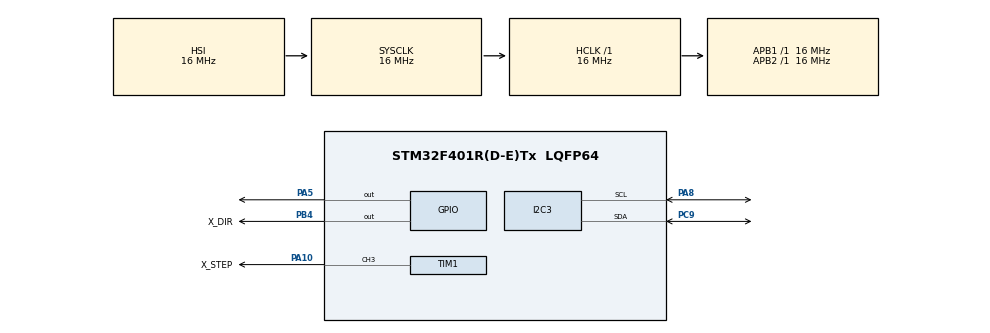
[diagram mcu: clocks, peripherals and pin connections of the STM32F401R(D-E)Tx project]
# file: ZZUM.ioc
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Mcu.Family=STM32F4
Mcu.Name=STM32F401R(D-E)Tx
Mcu.Package=LQFP64
NVIC.PriorityGroup=NVIC_PRIORITYGROUP_4
PA10.GPIO_Label=X_STEP
PA10.Signal=S_TIM1_CH3
PA5.Signal=GPIO_Output
PA8.Mode=I2C
PA8.Signal=I2C3_SCL
PB4.GPIO_Label=X_DIR
PB4.Signal=GPIO_Output
PC9.Mode=I2C
PC9.Signal=I2C3_SDA
ProjectManager.HeapSize=0x200
ProjectManager.StackSize=0x400
ProjectManager.TargetToolchain=STM32CubeIDE
RCC.AHBFreq_Value=16000000
RCC.APB1Freq_Value=16000000
RCC.APB2Freq_Value=16000000
RCC.CortexFreq_Value=16000000
RCC.HSE_VALUE=25000000
RCC.HSI_VALUE=16000000
RCC.LSE_VALUE=32768
RCC.SYSCLKFreq_VALUE=16000000
RCC.VCOOutputFreq_Value=192000000
SH.S_TIM1_CH3.0=TIM1_CH3,PWM Generation3 CH3
TIM1.Channel-PWM\ Generation3\ CH3=TIM_CHANNEL_3
board=custom

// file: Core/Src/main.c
/* USER CODE BEGIN Header */
/**
  ******************************************************************************
  * @file           : main.c
  * @brief          : Main program body
  ******************************************************************************
  * @attention
  *
  * Copyright (c) 2025 STMicroelectronics.
  * All rights reserved.
  *
  * This software is licensed under terms that can be found in the LICENSE file
  * in the root directory of this software component.
  * If no LICENSE file comes with this software, it is provided AS-IS.
  *
  ******************************************************************************
  */
/* USER CODE END Header */
#include "main.h"

I2C_HandleTypeDef hi2c3;

TIM_HandleTypeDef htim1;

void SystemClock_Config(void);
static void MX_GPIO_Init(void);
static void MX_TIM1_Init(void);
static void MX_I2C3_Init(void);

int main(void)
{

  /* MCU Configuration--------------------------------------------------------*/

  /* Reset of all peripherals, Initializes the Flash interface and the Systick. */
  HAL_Init();

  /* Configure the system clock */
  SystemClock_Config();

  /* Initialize all configured peripherals */
  MX_GPIO_Init();
  MX_TIM1_Init();
  MX_I2C3_Init();

  /* Infinite loop */
  /* USER CODE BEGIN WHILE */
  while (1)
  {
	  HAL_GPIO_TogglePin(GPIOA, GPIO_PIN_5); // LED
	  HAL_Delay(1000);                       // BLINK
    /* USER CODE END WHILE */

  }
}

void SystemClock_Config(void)
{
  RCC_OscInitTypeDef RCC_OscInitStruct = {0};
  RCC_ClkInitTypeDef RCC_ClkInitStruct = {0};

  /** Configure the main internal regulator output voltage
  */
  __HAL_RCC_PWR_CLK_ENABLE();
  __HAL_PWR_VOLTAGESCALING_CONFIG(PWR_REGULATOR_VOLTAGE_SCALE2);

  /** Initializes the RCC Oscillators according to the specified parameters
  * in the RCC_OscInitTypeDef structure.
  */
  RCC_OscInitStruct.OscillatorType = RCC_OSCILLATORTYPE_HSI;
  RCC_OscInitStruct.HSIState = RCC_HSI_ON;
  RCC_OscInitStruct.HSICalibrationValue = RCC_HSICALIBRATION_DEFAULT;
  RCC_OscInitStruct.PLL.PLLState = RCC_PLL_NONE;
  if (HAL_RCC_OscConfig(&RCC_OscInitStruct) != HAL_OK)
  {
    Error_Handler();
  }

  /** Initializes the CPU, AHB and APB buses clocks
  */
  RCC_ClkInitStruct.ClockType = RCC_CLOCKTYPE_HCLK|RCC_CLOCKTYPE_SYSCLK
                              |RCC_CLOCKTYPE_PCLK1|RCC_CLOCKTYPE_PCLK2;
  RCC_ClkInitStruct.SYSCLKSource = RCC_SYSCLKSOURCE_HSI;
  RCC_ClkInitStruct.AHBCLKDivider = RCC_SYSCLK_DIV1;
  RCC_ClkInitStruct.APB1CLKDivider = RCC_HCLK_DIV1;
  RCC_ClkInitStruct.APB2CLKDivider = RCC_HCLK_DIV1;

  if (HAL_RCC_ClockConfig(&RCC_ClkInitStruct, FLASH_LATENCY_0) != HAL_OK)
  {
    Error_Handler();
  }
}

static void MX_I2C3_Init(void)
{

  hi2c3.Instance = I2C3;
  hi2c3.Init.ClockSpeed = 100000;
  hi2c3.Init.DutyCycle = I2C_DUTYCYCLE_2;
  hi2c3.Init.OwnAddress1 = 0;
  hi2c3.Init.AddressingMode = I2C_ADDRESSINGMODE_7BIT;
  hi2c3.Init.DualAddressMode = I2C_DUALADDRESS_DISABLE;
  hi2c3.Init.OwnAddress2 = 0;
  hi2c3.Init.GeneralCallMode = I2C_GENERALCALL_DISABLE;
  hi2c3.Init.NoStretchMode = I2C_NOSTRETCH_DISABLE;
  if (HAL_I2C_Init(&hi2c3) != HAL_OK)
  {
    Error_Handler();
  }

}

static void MX_TIM1_Init(void)
{

  TIM_MasterConfigTypeDef sMasterConfig = {0};
  TIM_OC_InitTypeDef sConfigOC = {0};
  TIM_BreakDeadTimeConfigTypeDef sBreakDeadTimeConfig = {0};

  htim1.Instance = TIM1;
  htim1.Init.Prescaler = 0;
  htim1.Init.CounterMode = TIM_COUNTERMODE_UP;
  htim1.Init.Period = 65535;
  htim1.Init.ClockDivision = TIM_CLOCKDIVISION_DIV1;
  htim1.Init.RepetitionCounter = 0;
  htim1.Init.AutoReloadPreload = TIM_AUTORELOAD_PRELOAD_DISABLE;
  if (HAL_TIM_PWM_Init(&htim1) != HAL_OK)
  {
    Error_Handler();
  }
  sMasterConfig.MasterOutputTrigger = TIM_TRGO_RESET;
  sMasterConfig.MasterSlaveMode = TIM_MASTERSLAVEMODE_DISABLE;
  if (HAL_TIMEx_MasterConfigSynchronization(&htim1, &sMasterConfig) != HAL_OK)
  {
    Error_Handler();
  }
  sConfigOC.OCMode = TIM_OCMODE_PWM1;
  sConfigOC.Pulse = 0;
  sConfigOC.OCPolarity = TIM_OCPOLARITY_HIGH;
  sConfigOC.OCNPolarity = TIM_OCNPOLARITY_HIGH;
  sConfigOC.OCFastMode = TIM_OCFAST_DISABLE;
  sConfigOC.OCIdleState = TIM_OCIDLESTATE_RESET;
  sConfigOC.OCNIdleState = TIM_OCNIDLESTATE_RESET;
  if (HAL_TIM_PWM_ConfigChannel(&htim1, &sConfigOC, TIM_CHANNEL_3) != HAL_OK)
  {
    Error_Handler();
  }
  sBreakDeadTimeConfig.OffStateRunMode = TIM_OSSR_DISABLE;
  sBreakDeadTimeConfig.OffStateIDLEMode = TIM_OSSI_DISABLE;
  sBreakDeadTimeConfig.LockLevel = TIM_LOCKLEVEL_OFF;
  sBreakDeadTimeConfig.DeadTime = 0;
  sBreakDeadTimeConfig.BreakState = TIM_BREAK_DISABLE;
  sBreakDeadTimeConfig.BreakPolarity = TIM_BREAKPOLARITY_HIGH;
  sBreakDeadTimeConfig.AutomaticOutput = TIM_AUTOMATICOUTPUT_DISABLE;
  if (HAL_TIMEx_ConfigBreakDeadTime(&htim1, &sBreakDeadTimeConfig) != HAL_OK)
  {
    Error_Handler();
  }
  HAL_TIM_MspPostInit(&htim1);

}

static void MX_GPIO_Init(void)
{
  GPIO_InitTypeDef GPIO_InitStruct = {0};

  /* GPIO Ports Clock Enable */
  __HAL_RCC_GPIOA_CLK_ENABLE();
  __HAL_RCC_GPIOC_CLK_ENABLE();
  __HAL_RCC_GPIOB_CLK_ENABLE();

  /*Configure GPIO pin Output Level */
  HAL_GPIO_WritePin(GPIOA, GPIO_PIN_5, GPIO_PIN_RESET);

  /*Configure GPIO pin Output Level */
  HAL_GPIO_WritePin(X_DIR_GPIO_Port, X_DIR_Pin, GPIO_PIN_RESET);

  /*Configure GPIO pin : PA5 */
  GPIO_InitStruct.Pin = GPIO_PIN_5;
  GPIO_InitStruct.Mode = GPIO_MODE_OUTPUT_PP;
  GPIO_InitStruct.Pull = GPIO_NOPULL;
  GPIO_InitStruct.Speed = GPIO_SPEED_FREQ_LOW;
  HAL_GPIO_Init(GPIOA, &GPIO_InitStruct);

  /*Configure GPIO pin : X_DIR_Pin */
  GPIO_InitStruct.Pin = X_DIR_Pin;
  GPIO_InitStruct.Mode = GPIO_MODE_OUTPUT_PP;
  GPIO_InitStruct.Pull = GPIO_NOPULL;
  GPIO_InitStruct.Speed = GPIO_SPEED_FREQ_LOW;
  HAL_GPIO_Init(X_DIR_GPIO_Port, &GPIO_InitStruct);

}

void Error_Handler(void)
{
  __disable_irq();
  while (1)
  {
  }
}
